VERSION "All_Common"

NS_ :

BS_:

BU_: EPS PCM UNKNOWN

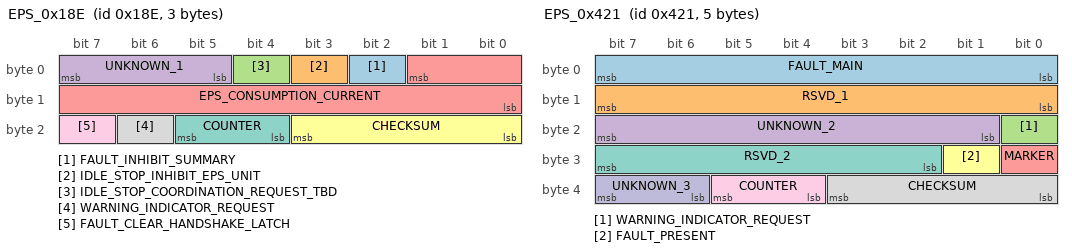
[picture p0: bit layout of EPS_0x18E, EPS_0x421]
BO_ 398 EPS_0x18E: 3 EPS
 SG_ FAULT_INHIBIT_SUMMARY : 2|1@1+ (1,0) [0|1] ""  PCM
 SG_ IDLE_STOP_INHIBIT_EPS_UNIT : 3|1@1+ (1,0) [0|1] ""  PCM
 SG_ IDLE_STOP_COORDINATION_REQUEST_TBD : 4|1@1+ (1,0) [0|1] ""  PCM
 SG_ UNKNOWN_1 : 5|3@1+ (1,0) [0|7] ""  PCM
 SG_ EPS_CONSUMPTION_CURRENT : 1|10@0+ (1,0) [0|1023] "raw"  PCM
 SG_ CHECKSUM : 16|4@1+ (1,0) [0|15] ""  PCM
 SG_ COUNTER : 20|2@1+ (1,0) [0|3] ""  PCM
 SG_ WARNING_INDICATOR_REQUEST : 22|1@1+ (1,0) [0|1] ""  PCM
 SG_ FAULT_CLEAR_HANDSHAKE_LATCH : 23|1@1+ (1,0) [0|1] ""  PCM

CM_ SG_ 398 EPS_CONSUMPTION_CURRENT "CANFI: EPS Consumption Current";
CM_ SG_ 398 IDLE_STOP_INHIBIT_EPS_UNIT "CANFI: Idle Stop Inhibit (EPS Unit)";
BO_ 1057 EPS_0x421: 5 EPS
 SG_ FAULT_MAIN : 0|8@1+ (1,0) [0|255] ""  UNKNOWN
 SG_ RSVD_1 : 8|8@1+ (1,0) [0|255] ""  UNKNOWN
 SG_ WARNING_INDICATOR_REQUEST : 16|1@1+ (1,0) [0|1] ""  UNKNOWN
 SG_ UNKNOWN_2 : 17|7@1+ (1,0) [0|127] ""  UNKNOWN
 SG_ MARKER : 24|1@1+ (1,0) [0|1] ""  UNKNOWN
 SG_ FAULT_PRESENT : 25|1@1+ (1,0) [0|1] ""  UNKNOWN
 SG_ RSVD_2 : 26|6@1+ (1,0) [0|63] ""  UNKNOWN
 SG_ CHECKSUM : 32|4@1+ (1,0) [0|15] ""  UNKNOWN
 SG_ COUNTER : 36|2@1+ (1,0) [0|3] ""  UNKNOWN
 SG_ UNKNOWN_3 : 38|2@1+ (1,0) [0|3] ""  UNKNOWN
